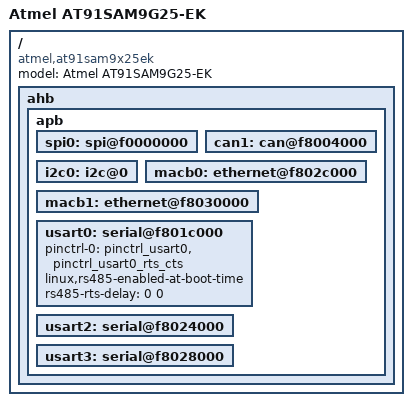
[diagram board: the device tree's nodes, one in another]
/*
 * at91sam9x25ek.dts - Device Tree file for AT91SAM9X25-EK board
 *
 *  Copyright (C) 2012 Atmel,
 *                2012 Nicolas Ferre <nicolas.ferre@atmel.com>
 *
 * Licensed under GPLv2 or later.
 */
/dts-v1/;
/include/ "at91sam9x25.dtsi"
/include/ "at91sam9x5ek.dtsi"

/ {
	model = "Atmel AT91SAM9G25-EK";
	compatible = "atmel,at91sam9x25ek", "atmel,at91sam9x5ek", "atmel,at91sam9x5", "atmel,at91sam9";

	ahb {
		apb {
			spi0: spi@f0000000 {
				status = "okay";
			};

			can1: can@f8004000 {
				status = "okay";
			};

			i2c0: i2c@0 {
				status = "okay";
			};

			macb0: ethernet@f802c000 {
				status = "okay";
			};

			macb1: ethernet@f8030000 {
				status = "okay";
			};

			usart0: serial@f801c000 {
				pinctrl-0 = <&pinctrl_usart0 &pinctrl_usart0_rts_cts>;
				linux,rs485-enabled-at-boot-time;
				rs485-rts-delay = <0 0>;
				status = "okay";
			};

			usart2: serial@f8024000 {
				status = "okay";
			};

			usart3: serial@f8028000 {
/*				pinctrl-0 = <&pinctrl_usart3 &pinctrl_usart3_rts_cts>;
				linux,rs485-enabled-at-boot-time;
				rs485-rts-delay = <0 0>;
*/
				status = "okay";
			};
		};
	};
};
